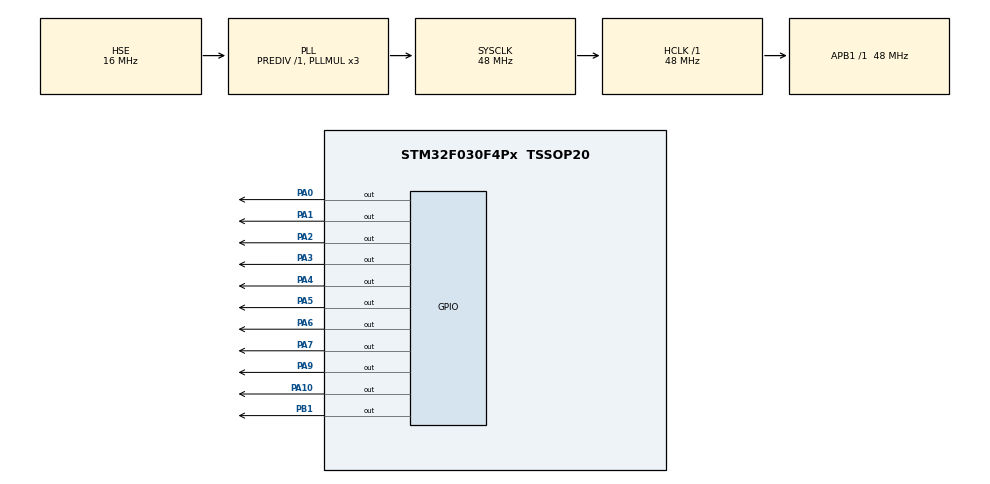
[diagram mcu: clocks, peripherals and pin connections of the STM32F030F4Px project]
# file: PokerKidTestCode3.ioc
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Mcu.Family=STM32F0
Mcu.Name=STM32F030F4Px
Mcu.Package=TSSOP20
PA0.Signal=GPIO_Output
PA1.Signal=GPIO_Output
PA10.Signal=GPIO_Output
PA13.Mode=Serial_Wire
PA13.Signal=SYS_SWDIO
PA14.Mode=Serial_Wire
PA14.Signal=SYS_SWCLK
PA2.Signal=GPIO_Output
PA3.Signal=GPIO_Output
PA4.Signal=GPIO_Output
PA5.Signal=GPIO_Output
PA6.Signal=GPIO_Output
PA7.Signal=GPIO_Output
PA9.Signal=GPIO_Output
PB1.Signal=GPIO_Output
PF0-OSC_IN.Mode=HSE-External-Oscillator
PF0-OSC_IN.Signal=RCC_OSC_IN
PF1-OSC_OUT.Mode=HSE-External-Oscillator
PF1-OSC_OUT.Signal=RCC_OSC_OUT
ProjectManager.HeapSize=0x200
ProjectManager.StackSize=0x400
ProjectManager.TargetToolchain=MDK-ARM V5
RCC.AHBFreq_Value=48000000
RCC.APB1Freq_Value=48000000
RCC.APB1TimFreq_Value=48000000
RCC.HCLKFreq_Value=48000000
RCC.HSE_VALUE=16000000
RCC.PLLMUL=RCC_PLL_MUL3
RCC.PLLSourceVirtual=RCC_PLLSOURCE_HSE
RCC.SYSCLKFreq_VALUE=48000000
RCC.SYSCLKSource=RCC_SYSCLKSOURCE_PLLCLK
board=PokerKidTestCode3

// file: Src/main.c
/**
  ******************************************************************************
  * @file           : main.c
  * @brief          : Main program body
  ******************************************************************************
  ** This notice applies to any and all portions of this file
  * that are not between comment pairs USER CODE BEGIN and
  * USER CODE END. Other portions of this file, whether
  * inserted by the user or by software development tools
  * are owned by their respective copyright owners.
  *
  * COPYRIGHT(c) 2018 STMicroelectronics
  *
  * Redistribution and use in source and binary forms, with or without modification,
  * are permitted provided that the following conditions are met:
  *   1. Redistributions of source code must retain the above copyright notice,
  *      this list of conditions and the following disclaimer.
  *   2. Redistributions in binary form must reproduce the above copyright notice,
  *      this list of conditions and the following disclaimer in the documentation
  *      and/or other materials provided with the distribution.
  *   3. Neither the name of STMicroelectronics nor the names of its contributors
  *      may be used to endorse or promote products derived from this software
  *      without specific prior written permission.
  *
  * THIS SOFTWARE IS PROVIDED BY THE COPYRIGHT HOLDERS AND CONTRIBUTORS "AS IS"
  * AND ANY EXPRESS OR IMPLIED WARRANTIES, INCLUDING, BUT NOT LIMITED TO, THE
  * IMPLIED WARRANTIES OF MERCHANTABILITY AND FITNESS FOR A PARTICULAR PURPOSE ARE
  * DISCLAIMED. IN NO EVENT SHALL THE COPYRIGHT HOLDER OR CONTRIBUTORS BE LIABLE
  * FOR ANY DIRECT, INDIRECT, INCIDENTAL, SPECIAL, EXEMPLARY, OR CONSEQUENTIAL
  * DAMAGES (INCLUDING, BUT NOT LIMITED TO, PROCUREMENT OF SUBSTITUTE GOODS OR
  * SERVICES; LOSS OF USE, DATA, OR PROFITS; OR BUSINESS INTERRUPTION) HOWEVER
  * CAUSED AND ON ANY THEORY OF LIABILITY, WHETHER IN CONTRACT, STRICT LIABILITY,
  * OR TORT (INCLUDING NEGLIGENCE OR OTHERWISE) ARISING IN ANY WAY OUT OF THE USE
  * OF THIS SOFTWARE, EVEN IF ADVISED OF THE POSSIBILITY OF SUCH DAMAGE.
  *
  ******************************************************************************
  */
#include "main.h"
#include "stm32f0xx_hal.h"

/* USER CODE BEGIN PV */
/* Private variables ---------------------------------------------------------*/

/* USER CODE END PV */

void SystemClock_Config(void);
static void MX_GPIO_Init(void);

/* USER CODE BEGIN PFP */
/* Private function prototypes -----------------------------------------------*/

/* USER CODE END PFP */

int main(void)
{

  /* MCU Configuration----------------------------------------------------------*/

  /* Reset of all peripherals, Initializes the Flash interface and the Systick. */
  HAL_Init();

  /* Configure the system clock */
  SystemClock_Config();

  /* Initialize all configured peripherals */
  MX_GPIO_Init();

  /* Infinite loop */
  /* USER CODE BEGIN WHILE */
  while (1){
		HAL_GPIO_WritePin(GPIOA, GPIO_PIN_10, 1); HAL_Delay(200); HAL_GPIO_WritePin(GPIOA, GPIO_PIN_10, 0); HAL_Delay(200);
		HAL_GPIO_WritePin(GPIOA, GPIO_PIN_9, 1); HAL_Delay(200); HAL_GPIO_WritePin(GPIOA, GPIO_PIN_9, 0); HAL_Delay(200);
		HAL_GPIO_WritePin(GPIOB, GPIO_PIN_1, 1); HAL_Delay(200); HAL_GPIO_WritePin(GPIOB, GPIO_PIN_1, 0); HAL_Delay(200);
		HAL_GPIO_WritePin(GPIOA, GPIO_PIN_7, 1); HAL_Delay(200); HAL_GPIO_WritePin(GPIOA, GPIO_PIN_7, 0); HAL_Delay(200);
		HAL_GPIO_WritePin(GPIOA, GPIO_PIN_6, 1); HAL_Delay(200); HAL_GPIO_WritePin(GPIOA, GPIO_PIN_6, 0); HAL_Delay(200);
		HAL_GPIO_WritePin(GPIOA, GPIO_PIN_5, 1); HAL_Delay(200); HAL_GPIO_WritePin(GPIOA, GPIO_PIN_5, 0); HAL_Delay(200);
		HAL_GPIO_WritePin(GPIOA, GPIO_PIN_0, 1); HAL_Delay(200); HAL_GPIO_WritePin(GPIOA, GPIO_PIN_0, 0); HAL_Delay(200);
		HAL_GPIO_WritePin(GPIOA, GPIO_PIN_1, 1); HAL_Delay(200); HAL_GPIO_WritePin(GPIOA, GPIO_PIN_1, 0); HAL_Delay(200);
		HAL_GPIO_WritePin(GPIOA, GPIO_PIN_2, 1); HAL_Delay(200); HAL_GPIO_WritePin(GPIOA, GPIO_PIN_2, 0); HAL_Delay(200);
		HAL_GPIO_WritePin(GPIOA, GPIO_PIN_3, 1); HAL_Delay(200); HAL_GPIO_WritePin(GPIOA, GPIO_PIN_3, 0); HAL_Delay(200);
		HAL_GPIO_WritePin(GPIOA, GPIO_PIN_4, 1); HAL_Delay(200); HAL_GPIO_WritePin(GPIOA, GPIO_PIN_4, 0); HAL_Delay(200);
  /* USER CODE END WHILE */

  }

}

void SystemClock_Config(void)
{

  RCC_OscInitTypeDef RCC_OscInitStruct;
  RCC_ClkInitTypeDef RCC_ClkInitStruct;

    /**Initializes the CPU, AHB and APB busses clocks
    */
  RCC_OscInitStruct.OscillatorType = RCC_OSCILLATORTYPE_HSE;
  RCC_OscInitStruct.HSEState = RCC_HSE_ON;
  RCC_OscInitStruct.PLL.PLLState = RCC_PLL_ON;
  RCC_OscInitStruct.PLL.PLLSource = RCC_PLLSOURCE_HSE;
  RCC_OscInitStruct.PLL.PLLMUL = RCC_PLL_MUL3;
  RCC_OscInitStruct.PLL.PREDIV = RCC_PREDIV_DIV1;
  if (HAL_RCC_OscConfig(&RCC_OscInitStruct) != HAL_OK)
  {
    _Error_Handler(__FILE__, __LINE__);
  }

    /**Initializes the CPU, AHB and APB busses clocks
    */
  RCC_ClkInitStruct.ClockType = RCC_CLOCKTYPE_HCLK|RCC_CLOCKTYPE_SYSCLK
                              |RCC_CLOCKTYPE_PCLK1;
  RCC_ClkInitStruct.SYSCLKSource = RCC_SYSCLKSOURCE_PLLCLK;
  RCC_ClkInitStruct.AHBCLKDivider = RCC_SYSCLK_DIV1;
  RCC_ClkInitStruct.APB1CLKDivider = RCC_HCLK_DIV1;

  if (HAL_RCC_ClockConfig(&RCC_ClkInitStruct, FLASH_LATENCY_1) != HAL_OK)
  {
    _Error_Handler(__FILE__, __LINE__);
  }

    /**Configure the Systick interrupt time
    */
  HAL_SYSTICK_Config(HAL_RCC_GetHCLKFreq()/1000);

    /**Configure the Systick
    */
  HAL_SYSTICK_CLKSourceConfig(SYSTICK_CLKSOURCE_HCLK);

  /* SysTick_IRQn interrupt configuration */
  HAL_NVIC_SetPriority(SysTick_IRQn, 0, 0);
}

/** Configure pins as
        * Analog
        * Input
        * Output
        * EVENT_OUT
        * EXTI
*/
static void MX_GPIO_Init(void)
{

  GPIO_InitTypeDef GPIO_InitStruct;

  /* GPIO Ports Clock Enable */
  __HAL_RCC_GPIOF_CLK_ENABLE();
  __HAL_RCC_GPIOA_CLK_ENABLE();
  __HAL_RCC_GPIOB_CLK_ENABLE();

  /*Configure GPIO pin Output Level */
  HAL_GPIO_WritePin(GPIOA, GPIO_PIN_0|GPIO_PIN_1|GPIO_PIN_2|GPIO_PIN_3
                          |GPIO_PIN_4|GPIO_PIN_5|GPIO_PIN_6|GPIO_PIN_7
                          |GPIO_PIN_9|GPIO_PIN_10, GPIO_PIN_RESET);

  /*Configure GPIO pin Output Level */
  HAL_GPIO_WritePin(GPIOB, GPIO_PIN_1, GPIO_PIN_RESET);

  /*Configure GPIO pins : PA0 PA1 PA2 PA3
                           PA4 PA5 PA6 PA7
                           PA9 PA10 */
  GPIO_InitStruct.Pin = GPIO_PIN_0|GPIO_PIN_1|GPIO_PIN_2|GPIO_PIN_3
                          |GPIO_PIN_4|GPIO_PIN_5|GPIO_PIN_6|GPIO_PIN_7
                          |GPIO_PIN_9|GPIO_PIN_10;
  GPIO_InitStruct.Mode = GPIO_MODE_OUTPUT_PP;
  GPIO_InitStruct.Pull = GPIO_NOPULL;
  GPIO_InitStruct.Speed = GPIO_SPEED_FREQ_LOW;
  HAL_GPIO_Init(GPIOA, &GPIO_InitStruct);

  /*Configure GPIO pin : PB1 */
  GPIO_InitStruct.Pin = GPIO_PIN_1;
  GPIO_InitStruct.Mode = GPIO_MODE_OUTPUT_PP;
  GPIO_InitStruct.Pull = GPIO_NOPULL;
  GPIO_InitStruct.Speed = GPIO_SPEED_FREQ_LOW;
  HAL_GPIO_Init(GPIOB, &GPIO_InitStruct);

}

void _Error_Handler(char *file, int line)
{
  while(1)
  {
  }
}

/************************ (C) COPYRIGHT STMicroelectronics *****END OF FILE****/
